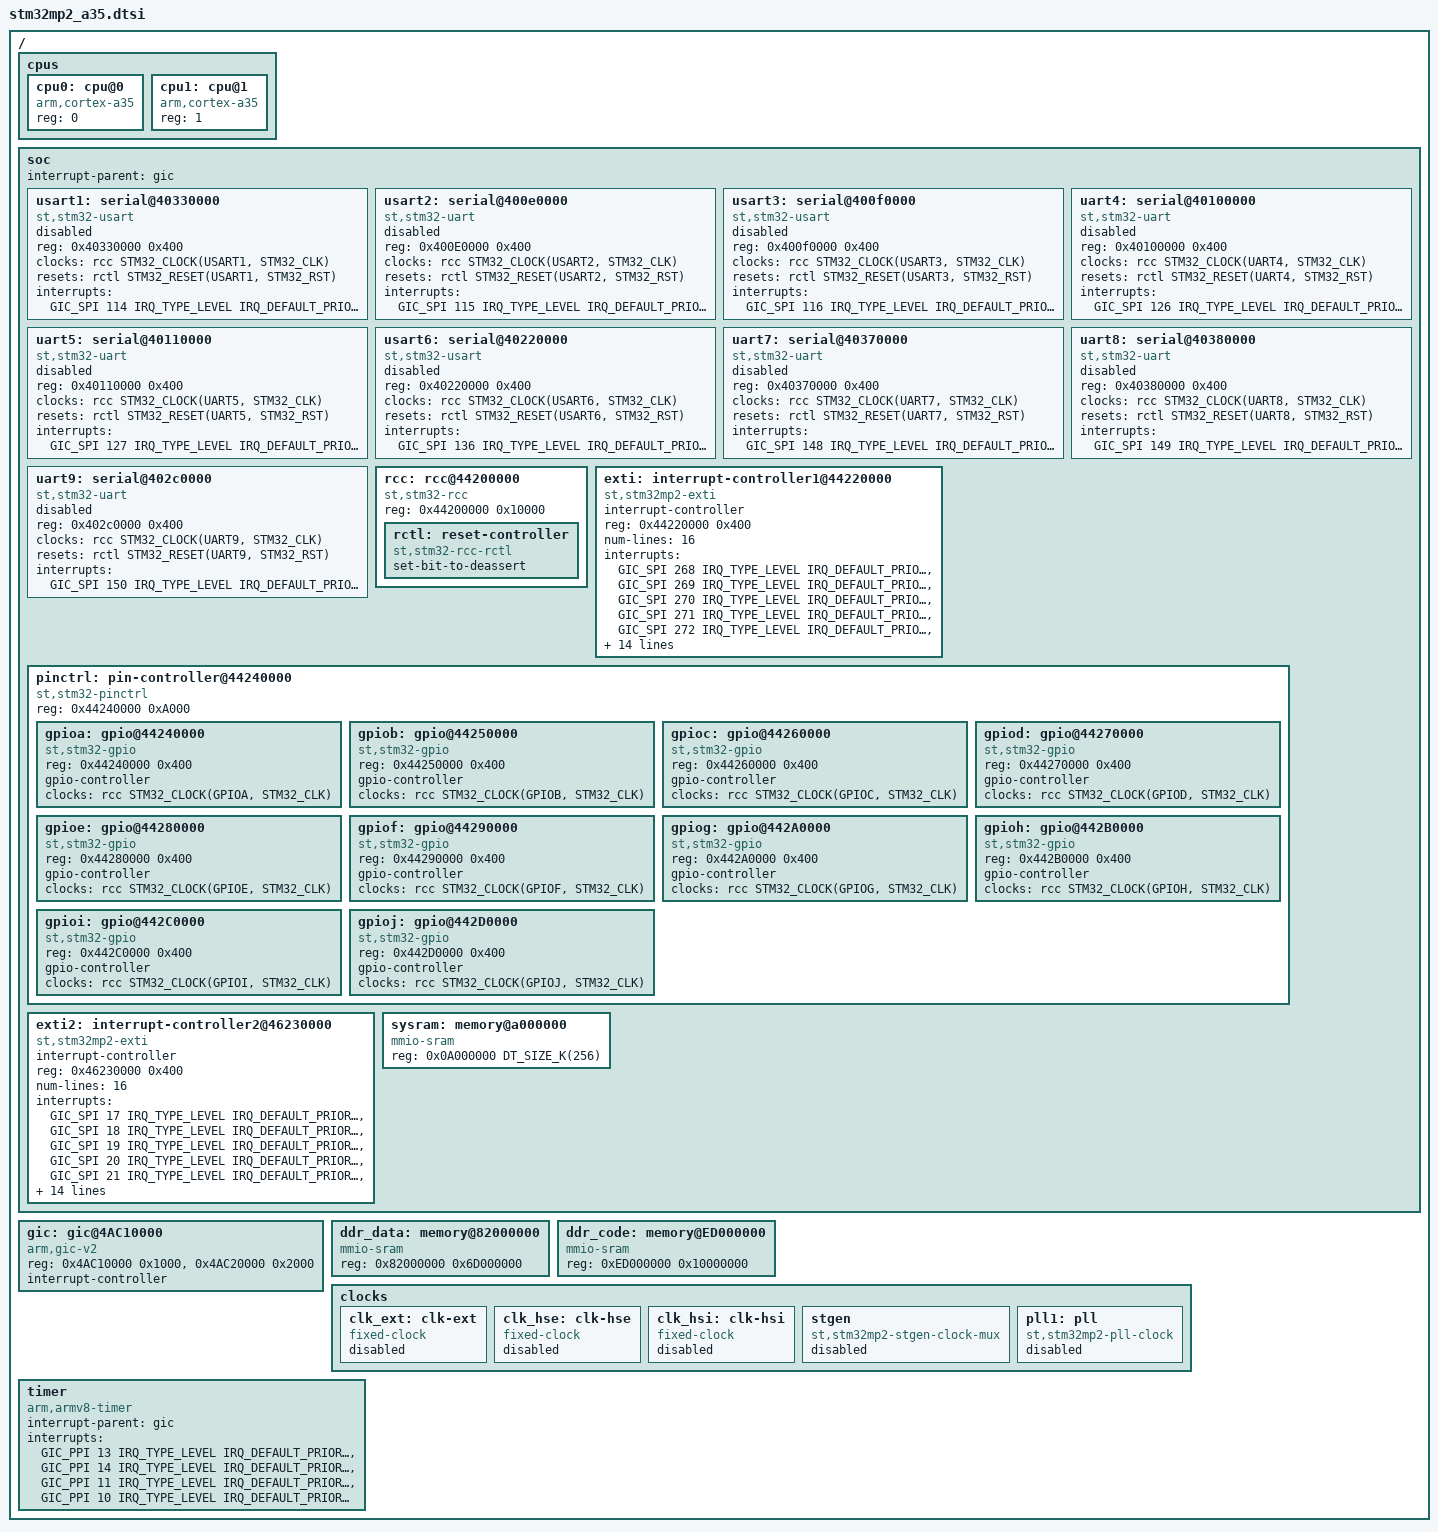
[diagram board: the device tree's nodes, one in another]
/*
 * Copyright (c) 2025 STMicroelectronics
 *
 * SPDX-License-Identifier: Apache-2.0
 */

#include <arm64/armv8-a.dtsi>

#include <freq.h>
#include <mem.h>

#include <zephyr/dt-bindings/clock/stm32mp2_clock.h>
#include <zephyr/dt-bindings/gpio/gpio.h>
#include <zephyr/dt-bindings/interrupt-controller/arm-gic.h>
#include <zephyr/dt-bindings/reset/stm32mp2_reset.h>

/ {
	cpus {
		#address-cells = <1>;
		#size-cells = <0>;

		cpu0: cpu@0 {
			compatible = "arm,cortex-a35";
			device_type = "cpu";
			reg = <0>;
		};

		cpu1: cpu@1 {
			compatible = "arm,cortex-a35";
			device_type = "cpu";
			reg = <1>;
		};
	};

	soc {
		interrupt-parent = <&gic>;

		usart1: serial@40330000 {
			compatible = "st,stm32-usart", "st,stm32-uart";
			reg = <0x40330000 0x400>;
			clocks = <&rcc STM32_CLOCK(USART1, STM32_CLK)>;
			resets = <&rctl STM32_RESET(USART1, STM32_RST)>;
			interrupts = <GIC_SPI 114 IRQ_TYPE_LEVEL IRQ_DEFAULT_PRIORITY>;
			status = "disabled";
		};

		usart2: serial@400e0000 {
			compatible = "st,stm32-uart";
			reg = <0x400E0000 0x400>;
			clocks = <&rcc STM32_CLOCK(USART2, STM32_CLK)>;
			resets = <&rctl STM32_RESET(USART2, STM32_RST)>;
			interrupts = <GIC_SPI 115 IRQ_TYPE_LEVEL IRQ_DEFAULT_PRIORITY>;
			status = "disabled";
		};

		usart3: serial@400f0000 {
			compatible = "st,stm32-usart", "st,stm32-uart";
			reg = <0x400f0000 0x400>;
			clocks = <&rcc STM32_CLOCK(USART3, STM32_CLK)>;
			resets = <&rctl STM32_RESET(USART3, STM32_RST)>;
			interrupts = <GIC_SPI 116 IRQ_TYPE_LEVEL IRQ_DEFAULT_PRIORITY>;
			status = "disabled";
		};

		uart4: serial@40100000 {
			compatible = "st,stm32-uart";
			reg = <0x40100000 0x400>;
			clocks = <&rcc STM32_CLOCK(UART4, STM32_CLK)>;
			resets = <&rctl STM32_RESET(UART4, STM32_RST)>;
			interrupts = <GIC_SPI 126 IRQ_TYPE_LEVEL IRQ_DEFAULT_PRIORITY>;
			status = "disabled";
		};

		uart5: serial@40110000 {
			compatible = "st,stm32-uart";
			reg = <0x40110000 0x400>;
			clocks = <&rcc STM32_CLOCK(UART5, STM32_CLK)>;
			resets = <&rctl STM32_RESET(UART5, STM32_RST)>;
			interrupts = <GIC_SPI 127 IRQ_TYPE_LEVEL IRQ_DEFAULT_PRIORITY>;
			status = "disabled";
		};

		usart6: serial@40220000 {
			compatible = "st,stm32-usart", "st,stm32-uart";
			reg = <0x40220000 0x400>;
			clocks = <&rcc STM32_CLOCK(USART6, STM32_CLK)>;
			resets = <&rctl STM32_RESET(USART6, STM32_RST)>;
			interrupts = <GIC_SPI 136 IRQ_TYPE_LEVEL IRQ_DEFAULT_PRIORITY>;
			status = "disabled";
		};

		uart7: serial@40370000 {
			compatible = "st,stm32-uart";
			reg = <0x40370000 0x400>;
			clocks = <&rcc STM32_CLOCK(UART7, STM32_CLK)>;
			resets = <&rctl STM32_RESET(UART7, STM32_RST)>;
			interrupts = <GIC_SPI 148 IRQ_TYPE_LEVEL IRQ_DEFAULT_PRIORITY>;
			status = "disabled";
		};

		uart8: serial@40380000 {
			compatible = "st,stm32-uart";
			reg = <0x40380000 0x400>;
			clocks = <&rcc STM32_CLOCK(UART8, STM32_CLK)>;
			resets = <&rctl STM32_RESET(UART8, STM32_RST)>;
			interrupts = <GIC_SPI 149 IRQ_TYPE_LEVEL IRQ_DEFAULT_PRIORITY>;
			status = "disabled";
		};

		uart9: serial@402c0000 {
			compatible = "st,stm32-uart";
			reg = <0x402c0000 0x400>;
			clocks = <&rcc STM32_CLOCK(UART9, STM32_CLK)>;
			resets = <&rctl STM32_RESET(UART9, STM32_RST)>;
			interrupts = <GIC_SPI 150 IRQ_TYPE_LEVEL IRQ_DEFAULT_PRIORITY>;
			status = "disabled";
		};

		rcc: rcc@44200000 {
			compatible = "st,stm32-rcc";
			reg = <0x44200000 0x10000>;
			#clock-cells = <2>;

			rctl: reset-controller {
				compatible = "st,stm32-rcc-rctl";
				#reset-cells = <1>;
				set-bit-to-deassert;
			};
		};

		exti: interrupt-controller1@44220000 {
			compatible =  "st,stm32mp2-exti","st,stm32-exti";
			interrupt-controller;
			#interrupt-cells = <1>;
			#address-cells = <1>;
			reg = <0x44220000 0x400>;
			num-lines = <16>;
			interrupts = <GIC_SPI 268 IRQ_TYPE_LEVEL IRQ_DEFAULT_PRIORITY>,
				     <GIC_SPI 269 IRQ_TYPE_LEVEL IRQ_DEFAULT_PRIORITY>,
				     <GIC_SPI 270 IRQ_TYPE_LEVEL IRQ_DEFAULT_PRIORITY>,
				     <GIC_SPI 271 IRQ_TYPE_LEVEL IRQ_DEFAULT_PRIORITY>,
				     <GIC_SPI 272 IRQ_TYPE_LEVEL IRQ_DEFAULT_PRIORITY>,
				     <GIC_SPI 273 IRQ_TYPE_LEVEL IRQ_DEFAULT_PRIORITY>,
				     <GIC_SPI 274 IRQ_TYPE_LEVEL IRQ_DEFAULT_PRIORITY>,
				     <GIC_SPI 275 IRQ_TYPE_LEVEL IRQ_DEFAULT_PRIORITY>,
				     <GIC_SPI 276 IRQ_TYPE_LEVEL IRQ_DEFAULT_PRIORITY>,
				     <GIC_SPI 277 IRQ_TYPE_LEVEL IRQ_DEFAULT_PRIORITY>,
				     <GIC_SPI 278 IRQ_TYPE_LEVEL IRQ_DEFAULT_PRIORITY>,
				     <GIC_SPI 279 IRQ_TYPE_LEVEL IRQ_DEFAULT_PRIORITY>,
				     <GIC_SPI 280 IRQ_TYPE_LEVEL IRQ_DEFAULT_PRIORITY>,
				     <GIC_SPI 281 IRQ_TYPE_LEVEL IRQ_DEFAULT_PRIORITY>,
				     <GIC_SPI 282 IRQ_TYPE_LEVEL IRQ_DEFAULT_PRIORITY>,
				     <GIC_SPI 283 IRQ_TYPE_LEVEL IRQ_DEFAULT_PRIORITY>;
			interrupt-names = "line0", "line1", "line2", "line3",
					  "line4", "line5", "line6", "line7",
					  "line8", "line9", "line10", "line11",
					  "line12", "line13", "line14", "line15";
			line-ranges = <0 1>, <1 1>, <2 1>, <3 1>,
				      <4 1>, <5 1>, <6 1>, <7 1>,
				      <8 1>, <9 1>, <10 1>, <11 1>,
				      <12 1>, <13 1>, <14 1>, <15 1>;
		};

		pinctrl: pin-controller@44240000{
			compatible = "st,stm32-pinctrl";
			reg = <0x44240000 0xA000>;
			#address-cells = <1>;
			#size-cells = <1>;

			gpioa: gpio@44240000  {
				compatible = "st,stm32-gpio";
				reg = <0x44240000 0x400>;
				gpio-controller;
				#gpio-cells = <2>;
				clocks = <&rcc STM32_CLOCK(GPIOA, STM32_CLK)>;
			};

			gpiob: gpio@44250000  {
				compatible = "st,stm32-gpio";
				reg = <0x44250000  0x400>;
				gpio-controller;
				#gpio-cells = <2>;
				clocks = <&rcc STM32_CLOCK(GPIOB, STM32_CLK)>;
			};

			gpioc: gpio@44260000  {
				compatible = "st,stm32-gpio";
				reg = <0x44260000 0x400>;
				gpio-controller;
				#gpio-cells = <2>;
				clocks = <&rcc STM32_CLOCK(GPIOC, STM32_CLK)>;
			};

			gpiod: gpio@44270000  {
				compatible = "st,stm32-gpio";
				reg = <0x44270000 0x400>;
				gpio-controller;
				#gpio-cells = <2>;
				clocks = <&rcc STM32_CLOCK(GPIOD, STM32_CLK)>;
			};

			gpioe: gpio@44280000  {
				compatible = "st,stm32-gpio";
				reg = <0x44280000 0x400>;
				gpio-controller;
				#gpio-cells = <2>;
				clocks = <&rcc STM32_CLOCK(GPIOE, STM32_CLK)>;
			};

			gpiof: gpio@44290000  {
				compatible = "st,stm32-gpio";
				reg = <0x44290000 0x400>;
				gpio-controller;
				#gpio-cells = <2>;
				clocks = <&rcc STM32_CLOCK(GPIOF, STM32_CLK)>;
			};

			gpiog: gpio@442A0000  {
				compatible = "st,stm32-gpio";
				reg = <0x442A0000 0x400>;
				gpio-controller;
				#gpio-cells = <2>;
				clocks = <&rcc STM32_CLOCK(GPIOG, STM32_CLK)>;
			};

			gpioh: gpio@442B0000  {
				compatible = "st,stm32-gpio";
				reg = <0x442B0000 0x400>;
				gpio-controller;
				#gpio-cells = <2>;
				clocks = <&rcc STM32_CLOCK(GPIOH, STM32_CLK)>;
			};

			gpioi: gpio@442C0000  {
				compatible = "st,stm32-gpio";
				reg = <0x442C0000 0x400>;
				gpio-controller;
				#gpio-cells = <2>;
				clocks = <&rcc STM32_CLOCK(GPIOI, STM32_CLK)>;
			};

			gpioj: gpio@442D0000 {
				compatible = "st,stm32-gpio";
				reg = <0x442D0000 0x400>;
				gpio-controller;
				#gpio-cells = <2>;
				clocks = <&rcc STM32_CLOCK(GPIOJ, STM32_CLK)>;
			};

		};

		exti2: interrupt-controller2@46230000 {
			compatible =  "st,stm32mp2-exti","st,stm32-exti";
			interrupt-controller;
			#interrupt-cells = <1>;
			#address-cells = <1>;
			reg = <0x46230000 0x400>;
			num-lines = <16>;
			interrupts = <GIC_SPI 17 IRQ_TYPE_LEVEL IRQ_DEFAULT_PRIORITY>,
				     <GIC_SPI 18 IRQ_TYPE_LEVEL IRQ_DEFAULT_PRIORITY>,
				     <GIC_SPI 19 IRQ_TYPE_LEVEL IRQ_DEFAULT_PRIORITY>,
				     <GIC_SPI 20 IRQ_TYPE_LEVEL IRQ_DEFAULT_PRIORITY>,
				     <GIC_SPI 21 IRQ_TYPE_LEVEL IRQ_DEFAULT_PRIORITY>,
				     <GIC_SPI 22 IRQ_TYPE_LEVEL IRQ_DEFAULT_PRIORITY>,
				     <GIC_SPI 23 IRQ_TYPE_LEVEL IRQ_DEFAULT_PRIORITY>,
				     <GIC_SPI 24 IRQ_TYPE_LEVEL IRQ_DEFAULT_PRIORITY>,
				     <GIC_SPI 25 IRQ_TYPE_LEVEL IRQ_DEFAULT_PRIORITY>,
				     <GIC_SPI 26 IRQ_TYPE_LEVEL IRQ_DEFAULT_PRIORITY>,
				     <GIC_SPI 27 IRQ_TYPE_LEVEL IRQ_DEFAULT_PRIORITY>,
				     <GIC_SPI 28 IRQ_TYPE_LEVEL IRQ_DEFAULT_PRIORITY>,
				     <GIC_SPI 29 IRQ_TYPE_LEVEL IRQ_DEFAULT_PRIORITY>,
				     <GIC_SPI 30 IRQ_TYPE_LEVEL IRQ_DEFAULT_PRIORITY>,
				     <GIC_SPI 31 IRQ_TYPE_LEVEL IRQ_DEFAULT_PRIORITY>,
				     <GIC_SPI 32 IRQ_TYPE_LEVEL IRQ_DEFAULT_PRIORITY>;
			interrupt-names = "line0", "line1", "line2", "line3",
					  "line4", "line5", "line6", "line7",
					  "line8", "line9", "line10", "line11",
					  "line12", "line13", "line14", "line15";
			line-ranges = <0 1>, <1 1>, <2 1>, <3 1>,
				      <4 1>, <5 1>, <6 1>, <7 1>,
				      <8 1>, <9 1>, <10 1>, <11 1>,
				      <12 1>, <13 1>, <14 1>, <15 1>;
		};

		sysram: memory@a000000  {
			compatible = "mmio-sram";
			reg = <0x0A000000 DT_SIZE_K(256)>;
		};

	};

	gic: gic@4AC10000 {
		compatible = "arm,gic-v2", "arm,gic";
		reg = <0x4AC10000 0x1000>,
			  <0x4AC20000 0x2000>;
		interrupt-controller;
		#interrupt-cells = <4>;
		status = "okay";
	};

	ddr_data: memory@82000000 {
		compatible = "mmio-sram";
		reg = <0x82000000 0x6D000000>;
	};

	ddr_code: memory@ED000000 {
		compatible = "mmio-sram";
		reg = <0xED000000 0x10000000>;
	};

	clocks {

		clk_ext: clk-ext {
			#clock-cells = <0>;
			compatible = "fixed-clock";
			status = "disabled";
		};

		clk_hse: clk-hse {
			#clock-cells = <0>;
			compatible = "fixed-clock";
			status = "disabled";
		};

		clk_hsi: clk-hsi {
			#clock-cells = <0>;
			compatible = "fixed-clock";
			status = "disabled";
		};

		stgen: stgen {
			#clock-cells = <0>;
			compatible = "st,stm32mp2-stgen-clock-mux";
			status = "disabled";
		};

		pll1: pll {
			#clock-cells = <0>;
			compatible = "st,stm32mp2-pll-clock";
			status = "disabled";
		};
	};

	timer {
		compatible = "arm,armv8-timer";
		interrupt-parent = <&gic>;
		interrupts = <GIC_PPI 13 IRQ_TYPE_LEVEL
					IRQ_DEFAULT_PRIORITY>,
					<GIC_PPI 14 IRQ_TYPE_LEVEL
					IRQ_DEFAULT_PRIORITY>,
					<GIC_PPI 11 IRQ_TYPE_LEVEL
					IRQ_DEFAULT_PRIORITY>,
					<GIC_PPI 10 IRQ_TYPE_LEVEL
					IRQ_DEFAULT_PRIORITY>;
	};
};
